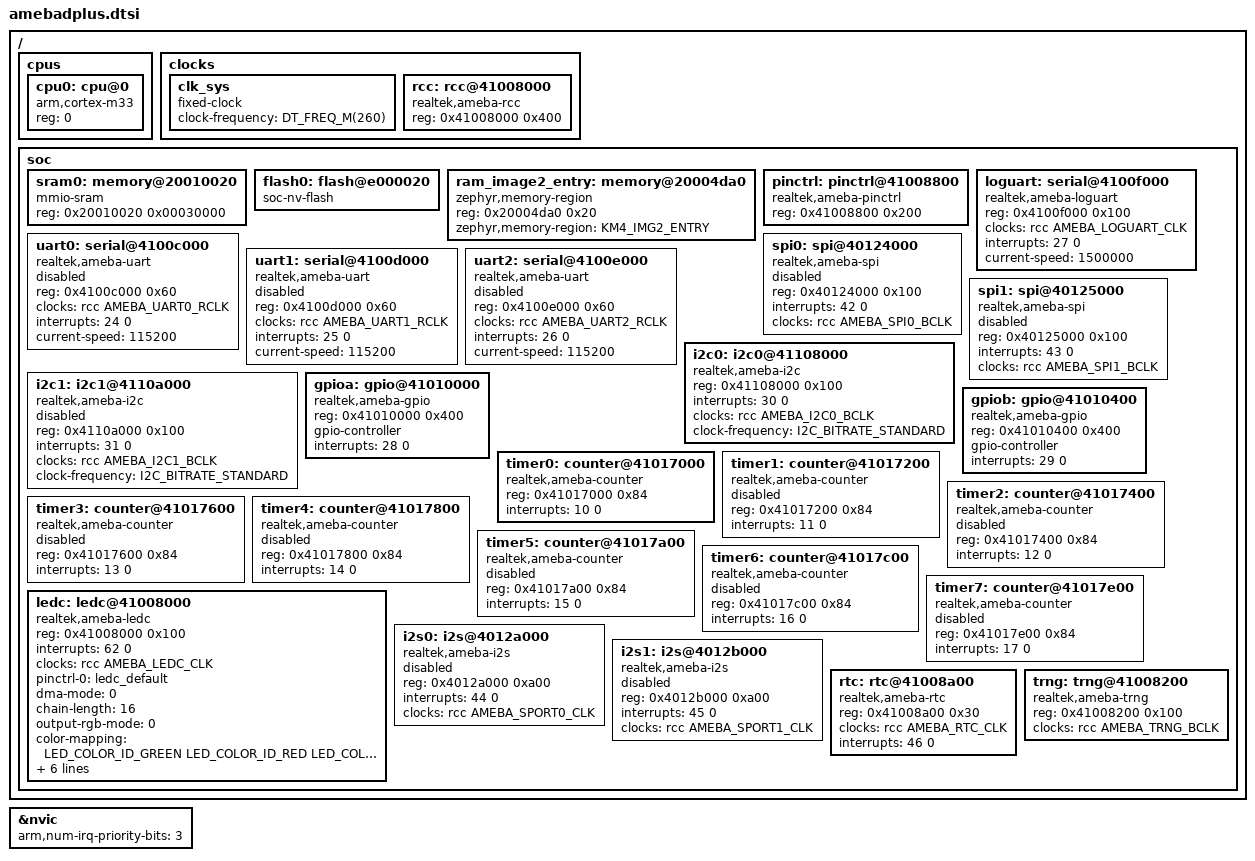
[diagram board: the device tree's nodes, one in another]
/*
 * Copyright (c) 2024 Realtek Semiconductor Corp.
 *
 * SPDX-License-Identifier: Apache-2.0
 */

#include <mem.h>
#include <freq.h>
#include <zephyr/dt-bindings/clock/amebadplus_clock.h>
#include <zephyr/dt-bindings/led/led.h>

#include <arm/armv8-m.dtsi>
#include <zephyr/dt-bindings/i2c/i2c.h>

/ {
	cpus {
		#address-cells = <1>;
		#size-cells = <0>;

		cpu0: cpu@0 {
			device_type = "cpu";
			compatible = "arm,cortex-m33";
			reg = <0>;
			#address-cells = <1>;
			#size-cells = <1>;
		};
	};

	clocks {
		#address-cells = <1>;
		#size-cells = <1>;

		clk_sys: clk_sys {
			#clock-cells = <0>;
			compatible = "fixed-clock";
			clock-frequency = <DT_FREQ_M(260)>;
		};

		rcc: rcc@41008000 {
			compatible = "realtek,ameba-rcc";
			#clock-cells = <1>;
			reg = <0x41008000 0x400>;
		};
	};

	soc {
		sram0: memory@20010020 {
			compatible = "mmio-sram";
			reg = <0x20010020 0x00030000>;
		};

		flash0: flash@e000020 {
			compatible = "soc-nv-flash";
		};

		ram_image2_entry: memory@20004da0 {
			compatible = "zephyr,memory-region";
			reg = <0x20004da0 0x20>;
			zephyr,memory-region = "KM4_IMG2_ENTRY";
		};

		pinctrl: pinctrl@41008800 {
			compatible = "realtek,ameba-pinctrl";
			reg = <0x41008800 0x200>;
		};

		loguart: serial@4100f000 {
			compatible = "realtek,ameba-loguart";
			reg = <0x4100f000 0x100>;
			clocks = <&rcc AMEBA_LOGUART_CLK>;
			interrupts = <27 0>;
			current-speed = <1500000>;
		};

		uart0: serial@4100c000 {
			compatible = "realtek,ameba-uart";
			reg = <0x4100c000 0x60>;
			clocks = <&rcc AMEBA_UART0_RCLK>;
			interrupts = <24 0>;
			current-speed = <115200>;
			status = "disabled";
		};

		uart1: serial@4100d000 {
			compatible = "realtek,ameba-uart";
			reg = <0x4100d000 0x60>;
			clocks = <&rcc AMEBA_UART1_RCLK>;
			interrupts = <25 0>;
			current-speed = <115200>;
			status = "disabled";
		};

		uart2: serial@4100e000 {
			compatible = "realtek,ameba-uart";
			reg = <0x4100e000 0x60>;
			clocks = <&rcc AMEBA_UART2_RCLK>;
			interrupts = <26 0>;
			current-speed = <115200>;
			status = "disabled";
		};

		spi0: spi@40124000 {
			compatible = "realtek,ameba-spi";
			reg = <0x40124000 0x100>;
			interrupts = <42 0>;
			clocks = <&rcc AMEBA_SPI0_BCLK>;
			#address-cells = <1>;
			#size-cells = <0>;
			status = "disabled";
		};

		spi1: spi@40125000 {
			compatible = "realtek,ameba-spi";
			reg = <0x40125000 0x100>;
			interrupts = <43 0>;
			clocks = <&rcc AMEBA_SPI1_BCLK>;
			#address-cells = <1>;
			#size-cells = <0>;
			status = "disabled";
		};

		i2c0: i2c0@41108000 {
			compatible = "realtek,ameba-i2c";
			reg = <0x41108000 0x100>;
			interrupts = <30 0>;
			clocks = <&rcc AMEBA_I2C0_BCLK>;
			clock-frequency = <I2C_BITRATE_STANDARD>;
			#address-cells = <1>;
			#size-cells = <0>;
			status = "okay";
		};

		i2c1: i2c1@4110a000 {
			compatible = "realtek,ameba-i2c";
			reg = <0x4110a000 0x100>;
			interrupts = <31 0>;
			clocks = <&rcc AMEBA_I2C1_BCLK>;
			clock-frequency = <I2C_BITRATE_STANDARD>;
			#address-cells = <1>;
			#size-cells = <0>;
			status = "disabled";
		};

		gpioa: gpio@41010000 {
			compatible = "realtek,ameba-gpio";
			reg = <0x41010000 0x400>;
			gpio-controller;
			#gpio-cells = <2>;
			interrupts = <28 0>;
		};

		gpiob: gpio@41010400 {
			compatible = "realtek,ameba-gpio";
			reg = <0x41010400 0x400>;
			gpio-controller;
			#gpio-cells = <2>;
			interrupts = <29 0>;
		};

		timer0: counter@41017000 {
			compatible = "realtek,ameba-counter";
			reg = <0x41017000 0x84>;
			interrupts = <10 0>;
			status = "okay";
		};

		timer1: counter@41017200 {
			compatible = "realtek,ameba-counter";
			reg = <0x41017200 0x84>;
			interrupts = <11 0>;
			status = "disabled";
		};

		timer2: counter@41017400 {
			compatible = "realtek,ameba-counter";
			reg = <0x41017400 0x84>;
			interrupts = <12 0>;
			status = "disabled";
		};

		timer3: counter@41017600 {
			compatible = "realtek,ameba-counter";
			reg = <0x41017600 0x84>;
			interrupts = <13 0>;
			status = "disabled";
		};

		timer4: counter@41017800 {
			compatible = "realtek,ameba-counter";
			reg = <0x41017800 0x84>;
			interrupts = <14 0>;
			status = "disabled";
		};

		timer5: counter@41017a00 {
			compatible = "realtek,ameba-counter";
			reg = <0x41017a00 0x84>;
			interrupts = <15 0>;
			status = "disabled";
		};

		timer6: counter@41017c00 {
			compatible = "realtek,ameba-counter";
			reg = <0x41017c00 0x84>;
			interrupts = <16 0>;
			status = "disabled";
		};

		timer7: counter@41017e00 {
			compatible = "realtek,ameba-counter";
			reg = <0x41017e00 0x84>;
			interrupts = <17 0>;
			status = "disabled";
		};

		ledc: ledc@41008000 {
			compatible = "realtek,ameba-ledc";
			reg = <0x41008000 0x100>;
			interrupts = <62 0>;
			clocks = <&rcc AMEBA_LEDC_CLK>;
			pinctrl-names = "default";
			pinctrl-0 = <&ledc_default>;
			dma-mode = <0>;
			chain-length = <16>;
			output-rgb-mode = <0>;
			color-mapping = <LED_COLOR_ID_GREEN
							LED_COLOR_ID_RED
							LED_COLOR_ID_BLUE>;
			wait-data-timeout = <0x3A97>;
			data-tx-time0h = <0xC>;
			data-tx-time0l = <0x18>;
			data-tx-time1h = <0x18>;
			data-tx-time1l = <0xC>;
			refresh-time = <0x3FFF>;
		};

		/* I2S RX */
		i2s0: i2s@4012a000 {
			compatible = "realtek,ameba-i2s";
			reg = <0x4012a000 0xa00>;
			interrupts = <44 0>;
			clocks = <&rcc AMEBA_SPORT0_CLK>;
			#address-cells = <1>;
			#size-cells = <0>;
			// dmas = <&dma0 2>;
			dma-names = "rx";
			status = "disabled";
		};

		/* I2S TX */
		i2s1: i2s@4012b000 {
			compatible = "realtek,ameba-i2s";
			reg = <0x4012b000 0xa00>;
			interrupts = <45 0>;
			clocks = <&rcc AMEBA_SPORT1_CLK>;
			#address-cells = <1>;
			#size-cells = <0>;
			// dmas = <&dma0 7>;
			dma-names = "tx";
			status = "disabled";
		};

		rtc: rtc@41008a00 {
			compatible = "realtek,ameba-rtc";
			reg = <0x41008a00 0x30>;
			clocks = <&rcc AMEBA_RTC_CLK>;
			interrupts = <46 0>;
		};

		trng: trng@41008200 {
			compatible = "realtek,ameba-trng";
			reg = <0x41008200 0x100>;
			clocks = <&rcc AMEBA_TRNG_BCLK>;
		};
	};
};

&nvic {
	arm,num-irq-priority-bits = <3>;
};
